# NANO112AN_v1 register map
File version: 1.0
Registers are 32-bit, read-write, reset 0x0 unless marked. A register's access mark holds for its fields unless they carry their own. Offsets are from the block's base; [hi:lo] are bit positions; {n}, {i} and the like mark numbered series.

## CLK — CLK Register Map
Base 0x50000200
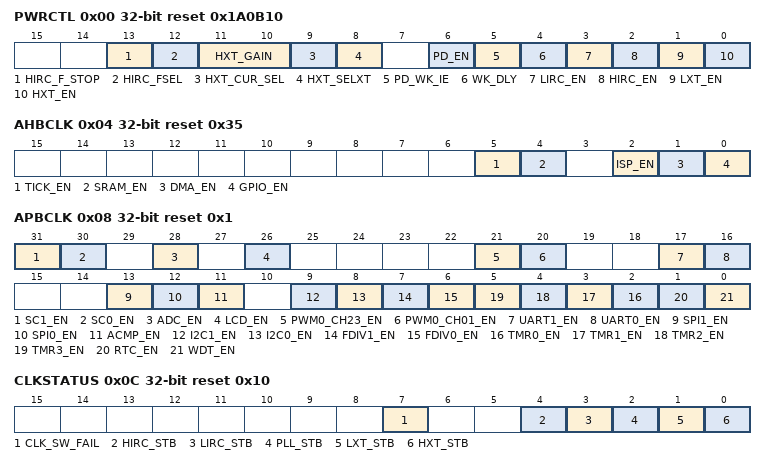
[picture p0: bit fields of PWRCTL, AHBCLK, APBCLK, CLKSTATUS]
0x00 PWRCTL reset 0x1A0B10 (reset mask 0xFFFFFFF0) — System Power-down Control Register
  [13] HIRC_F_STOP — HIRC Stop Output When Frequency Changes. This is a protected register. Please refer to open lock sequence to program it.
    0=HIRC will continue to output when HIRC frequency changes; 1=HIRC will suppress to output during first 16 clocks when HIRC frequency change
  [12] HIRC_FSEL — HIRC Output Frequency Select
    0=HIRC will output 12MHz clock; 1=HIRC will output 16MHz Clock
  [11:10] HXT_GAIN — HXT Gain Control Bit. This is a protected register. Please refer to open lock sequence to program it. Gain control is used to enlarge the gain of crystal to make sure crystal wok normally. If gain control is enabled, crystal will consume more power than gain control off.
    0=HXT frequency is lower than from 8 MHz; 1=HXT frequency is from 8 MHz to 12 MHz; 2=HXT frequency is from 12 MHz to 16 MHz; 3=HXT frequency is higher than 16 MHz
  [9] HXT_CUR_SEL — HXT Internal Current Selection. HXT has some internal current path to help crystal start-up. However when these currnet path existence, HXT will consume more power. User can use this bit to balance the start-up and power consumption. For 4 MHz to 16 MHz crystal.
    0=HXT current path always exists. HXT will consume more power; 1=HXT current path will exist 2ms then cut down. HXT will consume less power
  [8] HXT_SELXT — HXT SELXT. This is a protected register. Please refer to open lock sequence to program it.
    0=High frequency crystal loop back path Disabled. It is used for external oscillator; 1=High frequency crystal loop back path Enabled. It is used for external crystal
  [6] PD_EN — Chip Power-down Mode Enable Bit. This is a protected register. Please refer to open lock sequence to program it. When CPU sets this bit, the chip power down is enabled and chip will not enter Power-down mode until CPU sleep mode is also active. When chip wakes up from Power-down mode, this bit will be auto cleared. When chip is in Power-down mode, the LDO, HXT and HIRC will be disabled, but LXT and LIRC are not controlled by Power-down mode. When power down, the PLL and system clock (CPU, HCLKx and PCLKx) are also disabled no matter the Clock Source selection. Peripheral clocks are not controlled by this bit, if peripheral Clock Source is from LXT or LIRC. In Power-down mode, flash macro power is ON.
    0=Chip operated in Normal mode; 1=Chip power down Enabled
  [5] PD_WK_IE — Power-down Mode Wake-up Interrupt Enable Control. This is a protected register. Please refer to open lock sequence to program it. PD_WK_INT will be set if both PD_WK_IS and PD_WK_IE are high.
    0=Disabled; 1=Enabled
  [4] WK_DLY — Wake-up Delay Counter Enable Control. This is a protected register. Please refer to open lock sequence to program it. When chip wakes up from Power-down mode, the clock control will delay 4096 clock cycles to wait HXT stable or 16 clock cycles to wait HIRC stable.
    0=Delay clock cycle Disabled; 1=Delay clock cycle Enabled
  [3] LIRC_EN — LIRC Enable Control. This is a protected register. Please refer to open lock sequence to program it. LIRC is enabled by default.
    0=Disabled; 1=Enabled
  [2] HIRC_EN — HIRC Enable Control. This is a protected register. Please refer to open lock sequence to program it. HIRC is enabled by default.
    0=Disabled; 1=Enabled
  [1] LXT_EN — LXT Enable Control. This is a protected register. Please refer to open lock sequence to program it. LXT is disabled by default.
    0=Disabled; 1=Enabled
  [0] HXT_EN — HXT Enable Control. This is a protected register. Please refer to open lock sequence to program it. The bit default value is set by flash controller user configuration register config0 [26]. HXT is disabled by default.
    0=Disabled; 1=Enabled
0x04 AHBCLK reset 0x35 — AHB Devices Clock Enable Control Register
  [all] fields
    0=Disabled; 1=Enabled
  [5] TICK_EN — System Tick Clock Enable Control
  [4] SRAM_EN — SRAM Controller Clock Enable Control
  [2] ISP_EN — Flash ISP Controller Clock Enable Control
  [1] DMA_EN — DMA Controller Clock Enable Control
  [0] GPIO_EN — GPIO Controller Clock Enable Control
0x08 APBCLK reset 0x1 — APB Devices Clock Enable Control Register
  [all] fields
    0=Disabled; 1=Enabled
  [31] SC1_EN — SmartCard 1 Clock Enable Control
  [30] SC0_EN — SmartCard 0 Clock Enable Control
  [28] ADC_EN — Analog-digital-converter (ADC) Clock Enable Control
  [26] LCD_EN — LCD Controller Clock Enable Control
  [21] PWM0_CH23_EN — PWM0 Channel 2 and Channel 3 Clock Enable Control
  [20] PWM0_CH01_EN — PWM0 Channel 0 and Channel 1Clock Enable Control
  [17] UART1_EN — UART1 Clock Enable Control
  [16] UART0_EN — UART0 Clock Enable Control
  [13] SPI1_EN — SPI1 Clock Enable Control
  [12] SPI0_EN — SPI0 Clock Enable Control
  [11] ACMP_EN — ACMP Clock Enable Control
  [9] I2C1_EN — I2C1 Clock Enable Control
  [8] I2C0_EN — I2C0 Clock Enable Control
  [7] FDIV1_EN — Frequency Divider1 Output Clock Enable Control
  [6] FDIV0_EN — Frequency Divider0 Output Clock Enable Control
  [n+2] TMR{n}_EN (n=0..3) — Timer{n} Clock Enable Control
  [1] RTC_EN — Real-time-clock Clock Enable Control. This bit is used to control the RTC APB clock only, The RTC engine Clock Source is from LXT.
  [0] WDT_EN — Watchdog Timer Clock Enable Control. This is a protected register. Please refer to open lock sequence to program it. This bit is used to control the WDT APB clock only, The WDT engine Clock Source is from LIRC.
0x0C CLKSTATUS ro reset 0x10 (reset mask 0xFFFFFFF0) — Clock Status Monitor Register
  [7] CLK_SW_FAIL — Clock Switch Fail Flag. This bit will be set when target switch Clock Source is not stable. This bit is write 1 clear
    0=Clock switch success; 1=Clock switch fail
  [4] HIRC_STB — HIRC Clock Source Stable Flag
    0=HIRC clock is not stable or not enable; 1=HIRC clock is stable
  [3] LIRC_STB — LIRC Clock Source Stable Flag
    0=LIRC clock is not stable or not enable; 1=LIRC clock is stable
  [2] PLL_STB — PLL Clock Source Stable Flag
    0=PLL clock is not stable or not enable; 1=PLL clock is stable
  [1] LXT_STB — LXT Clock Source Stable Flag
    0=LXT clock is not stable or not enable; 1=LXT clock is stable
  [0] HXT_STB — HXT Clock Source Stable Flag
    0=HXT clock is not stable or not enable; 1=HXT clock is stable
0x10 CLKSEL0 (reset mask 0xFFFFFFF0) — Clock Source Select Control Register 0
  [2:0] HCLK_S — HCLK Clock Source Selection
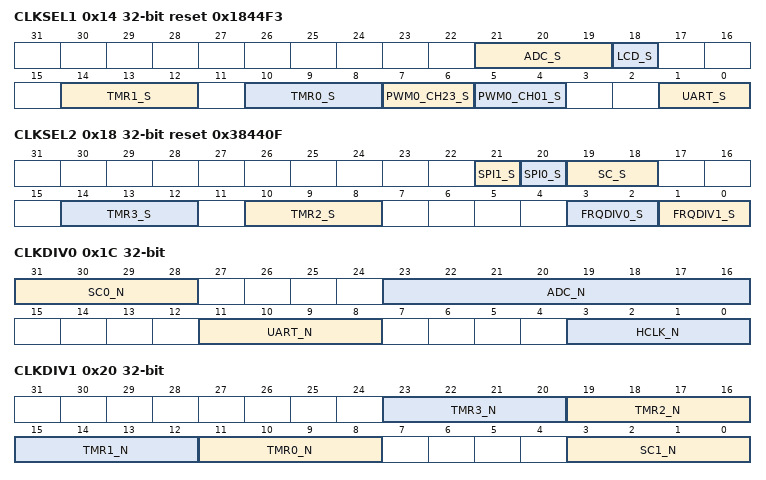
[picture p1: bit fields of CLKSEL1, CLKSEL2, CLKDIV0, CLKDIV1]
0x14 CLKSEL1 reset 0x1844F3 — Clock Source Select Control Register 1
  [21:19] ADC_S — ADC Clock Source Selection
  [18] LCD_S — LCD Clock Source Selection
    0=Clock Source from LXT
  [14:12] TMR1_S — Timer1 Clock Source Selection
  [10:8] TMR0_S — Timer0 Clock Source Selection
  [7:6] PWM0_CH23_S — PWM0 Channel 2 and Channel 3 Clock Source Selection
  [5:4] PWM0_CH01_S — PWM0 Channel 0 and Channel 1 Clock Source Selection
  [1:0] UART_S — UART 0/1 Clock Source Selection (UART0 and UART1 Use the Same Clock Source Selection)
0x18 CLKSEL2 reset 0x38440F — Clock Source Select Control Register 2
  [21] SPI1_S — SPI1 Clock Source Selection
    0=PLL; 1=HCLK
  [20] SPI0_S — SPI0 Clock Source Selection
    0=PLL; 1=HCLK
  [19:18] SC_S — SC Clock Source Selection
  [14:12] TMR3_S — Timer3 Clock Source Selection
  [10:8] TMR2_S — Timer2 Clock Source Selection
  [3:2] FRQDIV0_S — Clock Divider0 Clock Source Selection
  [1:0] FRQDIV1_S — Clock Divider Clock1 Source Selection
0x1C CLKDIV0 — Clock Divider Number Register 0
  [31:28] SC0_N — SC 0 Clock Divide Number From SC 0 Clock Source
  [23:16] ADC_N — ADC Clock Divide Number From ADC Clock Source
  [11:8] UART_N — UART Clock Divide Number From UART Clock Source
  [3:0] HCLK_N — HCLK Clock Divide Number From HCLK Clock Source
0x20 CLKDIV1 — Clock Divider Number Register 1
  [4n+11:4n+8] TMR{n}_N (n=0..3) — Timer{n} Clock Divide Number From Timer{n} Clock Source
  [3:0] SC1_N — SC 1 Clock Divide Number From SC 1 Clock Source
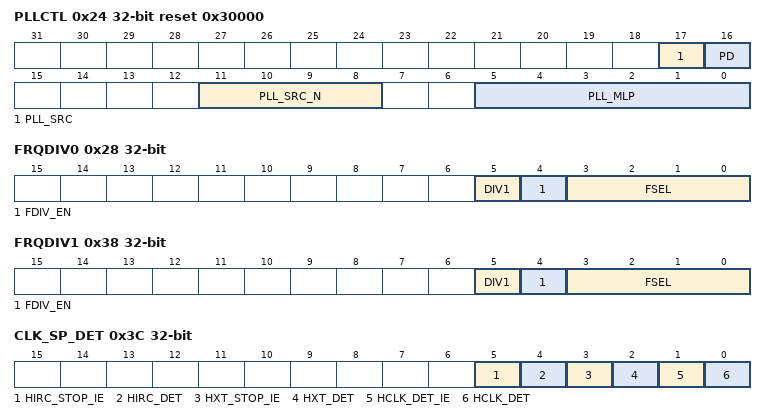
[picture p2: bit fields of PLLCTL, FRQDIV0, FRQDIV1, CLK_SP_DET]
0x24 PLLCTL reset 0x30000 — PLL Control Register
  [17] PLL_SRC — PLL Source Clock Select
    0=PLL source clock from HXT; 1=PLL source clock from HIRC
  [16] PD — Power-down Mode. If set the PD_EN bit "1" in PWR_CTL register, the PLL will enter Power-down mode too
    0=PLL is in normal mode; 1=PLL is in Power-down mode (default)
  [11:8] PLL_SRC_N — PLL Input Source Divider. PLL input clock frequency range: 0.8MHz ~ 2MHz
  [5:0] PLL_MLP — PLL Multiple. 000000: Reserved. 000001: X1. 000010: X2. 000011: X3. 000100: X4 ... 010000:X16 ... 100000: X32. 0thers: Reserved . PLL output frequency: PLL input frequency * PLL_MLP. PLL output frequency range: 16MHz ~ 32MHz
0x28 FRQDIV0 — Frequency Divider0 Control Register
  [5] DIV1 — Output Frequency Divied by 1
    0=Output frequency is equal to FCLK0; 1=Output frequency is equal to FRQDIV0_CLK
  [4] FDIV_EN — Frequency Divider Enable Bit
    0=Frequency Divider Disabled; 1=Frequency Divider Enabled
  [3:0] FSEL — Divider Output Frequency Selection Bits. The formula of output frequency is. Where FRQDIV0_CLK is the input clock frequency, Fout is the frequency of divider output clock and N is the 4-bit value of FSEL[3:0].
0x30 WK_INTSTS ro — Wake-up Interrupt Status
  [0] PD_WK_IS — Wake-up Interrupt Sstatus in Chip Power-down Mode. This bit indicates that some event resumes chip from Power-down mode. The status is set if external interrupts, UART, GPIO, RTC, USB, SPI, Timer, WDT, and BOD wake-up occurred. Write 1 to clear this bit.
0x34 APB_DIV — APB Clock Divider
  [2:0] APBDIV — APB Clock Divider. APB PCLK can be divided from HCLK.
0x38 FRQDIV1 — Frequency Divider1 Control Register
  [5] DIV1 — Output Frequency Divied by 1
    0=Output frequency is equal to FCLK1; 1=Output frequency is equal to FRQDIV1_CLK
  [4] FDIV_EN — Frequency Divider Enable Bit
    0=Frequency Divider Disabled; 1=Frequency Divider Enabled
  [3:0] FSEL — Divider Output Frequency Selection Bits. The formula of output frequency is. Where FRQDIV1_CLK is the input clock frequency, Fout is the frequency of divider output clock and N is the 4-bit value of FSEL[3:0].
0x3C CLK_SP_DET — Clock Stop Detect Control Register
  [5] HIRC_STOP_IE — HIRC Stop Detect Interrupt Enable Control
    0=HIRC stop detect interrupt Disabled; 1=HIRC stop detect interrupt Enabled
  [4] HIRC_DET — HIRC Stop Detect Enable Control
    0=HIRC stop detect Disabled; 1=HIRC stop detect Enabled
  [3] HXT_STOP_IE — HXT Stop Detect Interrupt Enable Control
    0=HXT stop detect interrupt Disabled; 1=HXT stop detect interrupt Enabled
  [2] HXT_DET — HXT Stop Detect Enable Control
    0=HXT stop detect Disabled; 1=HXT stop detect Enabled
  [1] HCLK_DET_IE — HCLK Stop Detect Interrupt Enable Control
    0=HCLK stop detect interrupt Disabled; 1=HCLK stop detect interrupt Enabled
  [0] HCLK_DET — HCLK Stop Detect Enable Control. Once HCLK stop detected, hardware will force HCLK from LIRC.
    0=HCLK stop detect Disabled; 1=HCLK stop detect Enabled
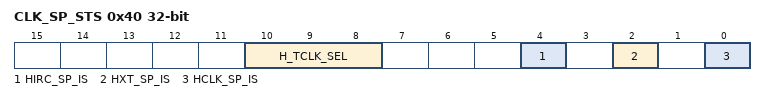
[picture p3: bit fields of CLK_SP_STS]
0x40 CLK_SP_STS ro — Clock Stop Detect Status Register
  [10:8] H_TCLK_SEL — HCLK Target Clock Select
  [4] HIRC_SP_IS — HIRC Stop Flag
    0=HIRC normal; 1=HIRC abnormal
  [2] HXT_SP_IS — HXT Stop Flag
    0=HXT normal; 1=HXT abnormal
  [0] HCLK_SP_IS — HCLK Clock Stop Flag
    0=HCLK normal; 1=HCLK abnormal
